# YTM32B1HA0 register map
Vendor: YTMicro; File version: 1.0
CPU: little endian, MPU, FPU, 2 interrupt priority bits
Registers are 32-bit, read-write, reset 0x0 unless marked. A register's access mark holds for its fields unless they carry their own. Offsets are from the block's base; [hi:lo] are bit positions; {n}, {i} and the like mark numbered series; 'fields as' and 'values as' point back to an identical list; <NAME> marks a mode.

## ENET (part 8 of 10) — Ethernet Quality-of-Service
Base 0x401E4000; register names take the prefix ENET_
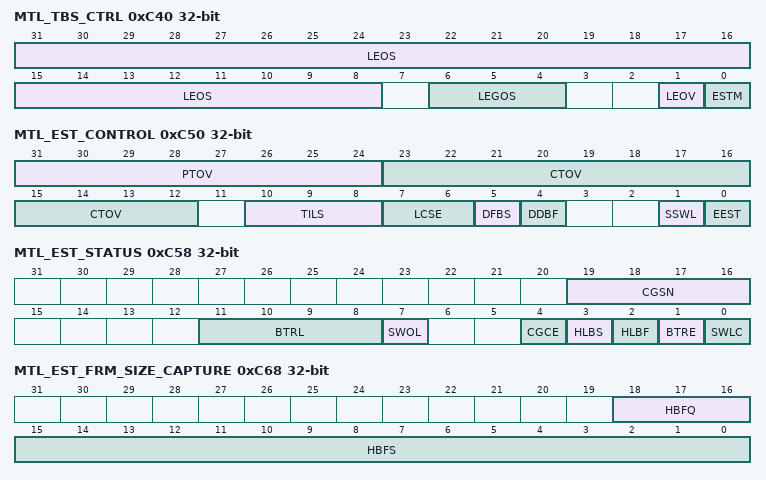
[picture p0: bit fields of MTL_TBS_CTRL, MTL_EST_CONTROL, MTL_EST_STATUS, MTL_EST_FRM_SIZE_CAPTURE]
0xC40 MTL_TBS_CTRL — This register controls the operation of Time Based Scheduling.
  [31:8] LEOS — The value in units of 256 nanoseconds that has to be added to the Launch time to compute the Launch Expiry time. Value valid only when LEOV is set. Max value: 999,999,999 ns, additionally should be smaller than CTR-1 value when ESTM mode is set since this value is a modulo CTR value.
  [6:4] LEGOS — The number GSN slots that has to be added to the Launch GSN to compute the Launch Expiry time. Value valid only when LEOV is set.
  [1] LEOV — When set indicates the LEOS field is valid. When not set, indicates the Launch Expiry Offset is not valid and the MTL must not check for Launch expiry time.
    0=LEOS field is invalid; 1=LEOS field is valid
  [0] ESTM — When this bit is set, the Launch Time value used in Time Based Scheduling is interpreted as an EST offset value and is added to the Base Time Register (BTR) of the current list. When reset, the Launch Time value is used as an absolute value that should be compared with the System time [39:8].
    0=EST offset Mode is disabled; 1=EST offset Mode is enabled
0xC50 MTL_EST_CONTROL — This register controls the operation of Enhancements to Scheduled Transmission (IEEE802.1Qbv).
  [31:24] PTOV — The value of PTP Clock period multiplied by 6 in nanoseconds. This value is needed to avoid transmission overruns at the beginning of the installation of a new GCL.
  [23:12] CTOV — Provides a 12 bit time offset value in nano second that is added to the current time to compensate for all the implementation pipeline delays such as the CDC sync delay, buffering delays, data path delays etc. This offset helps to ensure that the impact of gate controls is visible on the line exactly at the pre-determined schedule (or as close to the schedule as possible).
  [10:8] TILS — This field provides the left shift amount for the programmed Time Interval values used in the Gate Control Lists. ■ 000: No left shift needed (equal to x1ns) ■ 001: Left shift TI by 1 bit (equal to x2ns) ■ 010: Left shift TI by 2 bits (equal to x4ns) ■. ■. ■ 100: Left shift TI by 7 bits (equal to x128ns) Based on the configuration one or more bits of this field should be treated as Reserved/Read-Only.
  [7:6] LCSE — Programmable number of GCL list iterations before reporting an HLBS error defined in EST_Status register.
    0=4 iterations; 1=8 iterations; 2=16 iterations; 3=32 iterations
  [5] DFBS — When set frames reported to cause HOL Blocking due to not getting scheduled (HLBS field of EST_Status register) after 4,8,16,32 (based on LCSE field of this register) GCL iterations are dropped.
    0=Do not Drop Frames causing Scheduling Error; 1=Drop Frames causing Scheduling Error
  [4] DDBF — When set, frames are not be dropped during Head-of-Line blocking due to Frame Size Error (HLBF field of EST_Status register).
    0=Drop frames during Frame Size Error; 1=Do not Drop frames during Frame Size Error
  [1] SSWL — When set indicates that the software has programmed that list that it currently owns (SWOL) and the hardware should switch to the new list based on the new BTR. Hardware clears this bit when the switch to the SWOL happens to indicate the completion of the switch or when an BTR error (BTRE in Status register) is set. When BTRE is set this bit is cleared but SWOL is not updated as the switch was not successful. Access restriction applies. Setting 1 sets. Self-cleared. Setting 0 has no effect.
    0=Switch to S/W owned list is disabled; 1=Switch to S/W owned list is enabled
  [0] EEST — When reset, the gate control list processing is halted and all gates are assumed to be in Open state. Should be set for the hardware to start processing the gate control lists. During the toggle from 0 to 1, the gate control list processing starts only after the SSWL bit it set. When DWC_EQOS_ASP_ECC is selected during the configuration, if any uncorrectable error is detected in the EST memory the hardware will reset this bit and disable the EST function.
    0=EST is disabled; 1=EST is enabled
0xC58 MTL_EST_STATUS ro — This register provides Status related to Enhancements to Scheduled Transmission (IEEE802.1Qbv).
  [19:16] CGSN rw — Indicates the slot number of the GCL list. Slot number is a modulo 16 count of the GCL List loops executed so far. Even if a new GCL list is installed, the count is incremental.
  [11:8] BTRL rw — Provides the minimum count (N) for which the equation Current Time =< New BTR + (N * New Cycle Time) becomes true. N = "1111" indicates the iterations exceeded the value of 8 and the hardware was not able to update New BTR to be equal to or greater than Current Time. Software intervention is needed to update the New BTR. Value cleared when BTRE field of this register is cleared.
  [7] SWOL rw — When '0' indicates Gate control list number "0" is owned by software and when "1" indicates the Gate Control list "1" is owned by the software. Any reads/writes by the software (using indirect access via GCL_Control) is directed to the list indicated by this value by default. The inverse of this value is treated as HWOL. R/W operations performed by hardware are directed to the list pointed by HWOL by default.
    0=Gate control list number "0" is owned by software; 1=Gate control list number "1" is owned by software
  [4] CGCE rw — This error occurs when the list length (LLR) is 1 and the programmed Time Interval (TI) value after the optional Left Shifting is less than or equal to the Cycle Time (CTR). The above programming implies Gates are either always Closed or always Open based on the Gate Control values; the same effect can be achieved by other simpler (non TSN) programming mechanisms. Since the implementation does not support such a programming an error is reported. Access restriction applies. Self-set to 1 on internal event. Setting 1 clears. Setting 0 has no effect.
    0=Constant Gate Control Error not detected; 1=Constant Gate Control Error detected
  [3] HLBS rw — Set when the frame is not able to win arbitration and get scheduled even after 4 iterations of the GCL. Indicates to software a potential programming error. The one hot encoded values of the Queue Numbers that are not able to make progress are indicated in the MTL_EST_Sch_Error register. Bit cleared when MTL_EST_Sch_Error register is all zeros.
    0=Head-Of-Line Blocking due to Sched- uling not detected; 1=Head-Of-Line Blocking due to Scheduling detected
  [2] HLBF rw — Set when HOL Blocking is noticed on one or more Queues as a result of none of the Time Intervals of gate open in the GCL being greater than or equal to the duration needed for frame size (or frame fragment size when preemption is enabled) transmission. The one hot encoded Queue numbers that are experiencing HLBF are indicated in the MTL_EST_Frm_Size_Error register. Additionally, the first Queue number that experienced HLBF along with the frame size is captured in MTL_EST_Frm_Size_Capture register. Bit cleared when MTL_EST_Frame_Size_ Error register is all zeros.
    0=Head-Of-Line Blocking due to Frame Size not detected; 1=Head-Of-Line Blocking due to Frame Size detected
  [1] BTRE rw — When "1" indicates a programming error in the BTR of SWOL where the programmed value is less than current time. If the BTRL = "1111", SWOL is not updated and Software should reprogram the BTR to a value greater than current time and then set SSWL to reinitiate the switch to SWOL. Else if the value of BTRL < "1111", SWOL is updated and this field indicates the number of iterations (of + CycleTime) taken by hardware to update the BTR to a value greater than Current Time. Access restriction applies. Self-set to 1 on internal event. Setting 1 clears. Setting 0 has no effect.
    0=BTR Error not detected; 1=BTR Error detected
  [0] SWLC rw — When "1" indicates the hardware has successfully switched to the SWOL, and the SWOL bit has been updated to that effect. Cleared when the SSWL of EST_Control register transitions from 0 to 1, or on a software write. Access restriction applies. Self-set to 1 on internal event. Setting 1 clears. Setting 0 has no effect.
    0=Switch to S/W owned list is not complete; 1=Switch to S/W owned list is complete
0xC60 MTL_EST_SCH_ERROR ro — This register provides the One Hot encoded Queue Numbers that are having the Scheduling related error (timeout).
  [2:0] SEQN rw — The One Hot Encoded Queue Numbers that have experienced error/timeout described in HLBS field of status register. Access restriction applies. Self-set to 1 on internal event. Setting 1 clears. Setting 0 has no effect.
0xC64 MTL_EST_FRM_SIZE_ERROR — This register provides the One Hot encoded Queue Numbers that are having the Frame Size related error.
  [2:0] FEQN — The One Hot Encoded Queue Numbers that have experienced error described in HLBF field of status register. Access restriction applies. Self-set to 1 on internal event. Setting 1 clears. Setting 0 has no effect.
0xC68 MTL_EST_FRM_SIZE_CAPTURE — This register captures the Frame Size and Queue Number of the first occurrence of the Frame Size related error. Up on clearing it captures the data of immediate next occurrence of a similar error.
  [18:16] HBFQ — Captures the binary value of the of the first Queue (number) experiencing HLBF error (see HLBF field of status register). Value once written is not altered by any subsequent queue errors of similar nature. Once cleared the queue number of the next occurring HLBF error is captured. Width is based on the number of Tx Queues configured; remaining bits are Read-Only. Cleared when MTL_EST_Frm_Size_Error register is all zeros.
  [15:0] HBFS — Captures the Frame Size of the dropped frame related to queue number indicated in HBFQ field of this register. Contents of this register should be considered invalid, if this field is zero. Cleared when MTL_EST_Frm_Size_Error register is all zeros.
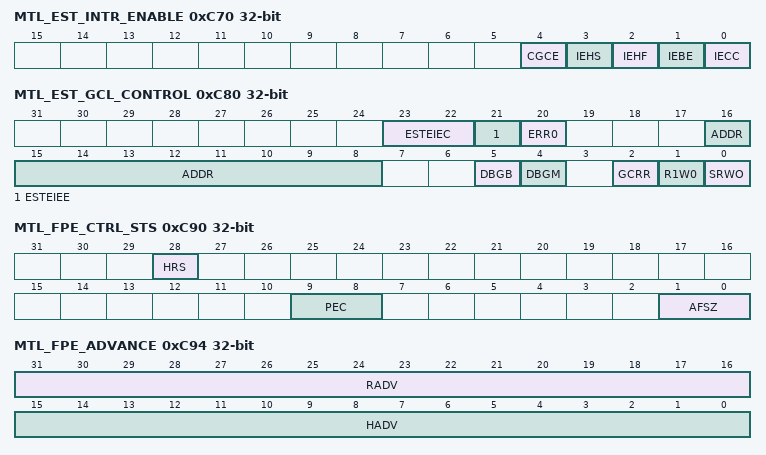
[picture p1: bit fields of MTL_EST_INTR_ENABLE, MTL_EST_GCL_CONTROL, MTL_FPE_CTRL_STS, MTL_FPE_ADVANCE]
0xC70 MTL_EST_INTR_ENABLE — This register implements the Interrupt Enable bits for the various events that generate an interrupt. Bit positions have a 1 to 1 correlation with the status bit positions in MTL_ETS_Status register.
  [4] CGCE — When set, generates interrupt when the Constant Gate Control Error occurs and is indicated in the status. When reset this event does not generate an interrupt
    0=Interrupt for CGCE is disabled; 1=Interrupt for CGCE is enabled
  [3] IEHS — When set, generates interrupt when the Head-of-Line Blocking due to Scheduling issue and is indicated in the status. When reset this event does not generate an interrupt.
    0=Interrupt for HLBS is disabled; 1=Interrupt for HLBS is enabled
  [2] IEHF — When set, generates interrupt when the Head-of-Line Blocking due to Frame Size error occurs and is indicated in the status. When reset this event does not generate an interrupt.
    0=Interrupt for HLBF is disabled; 1=Interrupt for HLBF is enabled
  [1] IEBE — When set, generates interrupt when the BTR Error occurs and is indicated in the status. When reset this event does not generate an interrupt.
    0=Interrupt for BTR Error is disabled; 1=Interrupt for BTR Error is enabled
  [0] IECC — When set, generates interrupt when the configuration change is successful and the hardware has switched to the new list. When reset this event does not generate an interrupt.
    0=Interrupt for Switch List is disabled; 1=Interrupt for Switch List is enabled
0xC80 MTL_EST_GCL_CONTROL — This register provides the control information for reading/writing to the Gate Control lists.
  [23:22] ESTEIEC — When EIEE bit of this register is set, following are the errors inserted based on the value encoded in this field. This filed will be valid only if DWC_EQOS_ASP_ECC feature is selected during the configuration, else it will be reserved.
    0=Insert 1 bit error; 1=Insert 2 bit errors; 2=Insert 3 bit errors; 3=Insert 1 bit error in address field
  [21] ESTEIEE — When set along with EEST bit of MTL_EST_Control register, enables the ECC error injection feature. When reset, disables the ECC error injection feature.
    0=EST ECC Inject Error is disabled; 1=EST ECC Inject Error is enabled
  [20] ERR0 — When set indicates the last write operation was aborted as software writes to GCL and GCL registers is prohibited when SSWL bit of MTL_EST_Control Register is set. Access restriction applies. Self-set to 1 on internal event. Setting 1 clears. Setting 0 has no effect.
    0=ERR0 is disabled; 1=ERR1 is enabled
  [16:8] ADDR — Gate Control List Address: (GCLA when GCRR is "0"). Provides the address (row number) of the Gate Control List at which the R/W operation has to be performed. By default the Gate Control List pointed by SWOL of MTL_EST_Status is selected for R/W, however if the DBGM bit of this register is set, a debug mode access is given to R/W from DBGB. The width of this field is dependent on DWC_EQOS_EST_DEP; unused bits should be treated as read only. Gate Control list Related Registers Address: (GCRA when GCRR is "1"). By default the GCL related register set pointed by SWOL of MTL_EST_Status is selected for R/W, however if the DBGM bit of this register is set, a debug mode access is given to R/W from DBGB. Lower 3 bits are only used in this mode, higher order bits are treated as dont cares. ■ 000: BTR Low (31:0) ■ 001: BTR High (63:31) ■ 010: CTR Low (31:0) ■ 011: CTR High (39:32) ■ 100: TER (31:0) ■ 101: LLR (n:0) (where n is (log{DWC_EQOS_EST_DEP} / log2)) ■ Others: Reserved
  [5] DBGB — When set to "0" indicates R/W in debug mode should be directed to Bank 0 (GCL0 and corresponding Time related registers). When set to "1" indicates R/W in debug mode should be directed to Bank 1 (GCL1 and corresponding Time related registers). This value is used when DBGM is set and overrides by value of SWOL which is normally used.
  [4] DBGM — When set to "1" indicates R/W in debug mode where the memory bank (for GCL and Time related registers) is explicitly provided by DBGB value, when set to "0" SWOL bit is used to determine which bank to use.
    0=Debug Mode is disabled; 1=Debug Mode is enabled
  [2] GCRR — When set to "1" indicates the R/W access is for the GCL related registers (BTR, CTR, TER, LLR) whose address is provided by GCRA. When "0" indicates R/W should be directed to GCL from the address provided by GCLA.
    0=Gate Control Related Registers are disabled; 1=Gate Control Related Registers are enabled
  [1] R1W0 — When set to '1': Read Operation When set to '0': Write Operation.
    0=Write Operation; 1=Read Operation
  [0] SRWO — When set indicates a Read/Write Op has started and is in progress. When reset by hardware indicates the R/W Op has completed or an error has occurred (when bit 20 is set) Reads: Data can be read from MTL_EST_GCL_Data register after this bit is reset Writes: MTL_EST_GCL_Data should be programmed with write data before setting SRWO. Access restriction applies. Setting 1 sets. Self-cleared. Setting 0 has no effect.
    0=Start Read/Write Op disabled; 1=Start Read/Write Op enabled
0xC84 MTL_EST_GCL_DATA — This register holds the read data or write data in case of reads and writes respectively.
  [31:0] GCD — The data corresponding to the address selected in the GCL_Control register. Used for both Read and Write operations.
0xC90 MTL_FPE_CTRL_STS — This register controls the operation of, and provides status for Frame Preemption (IEEE802.1Qbu/802.3br).
  [28] HRS ro — ■ 1: Indicates a Set-and-Hold-MAC operation was last executed and the pMAC is in Hold State. ■ 0: Indicates a Set-and-Release-MAC operation was last executed and the pMAC is in Release State.
    0=Indicates a Set-and-Release-MAC operation was last executed and the pMAC is in Release State; 1=Indicates a Set-and-Hold-MAC operation was last executed and the pMAC is in Hold State
  [9:8] PEC — When set indicates the corresponding Queue must be classified as preemptable, when '0' Queue is classified as express. When both EST (Qbv) and Preemption are enabled, Queue-0 is always assumed to be preemptable. When EST (Qbv) is enabled Queues categorized as preemptable here are always assumed to be in "Open" state in the Gate Control List.
  [1:0] AFSZ — used to indicate, in units of 64 bytes, the minimum number of bytes over 64 bytes required in non-final fragments of preempted frames. The minimum non-final fragment size is (AFSZ +1) * 64 bytes
0xC94 MTL_FPE_ADVANCE — This register holds the Hold and Release Advance time.
  [31:16] RADV — The maximum time in nanoseconds that can elapse between issuing a RELEASE to the MAC and the MAC being ready to resume transmission of preemptable frames, in the absence of there being any express frames available for transmission.
  [15:0] HADV — The maximum time in nanoseconds that can elapse between issuing a HOLD to the MAC and the MAC ceasing to transmit any preemptable frame that is in the process of transmission or any preemptable frames that are queued for transmission.
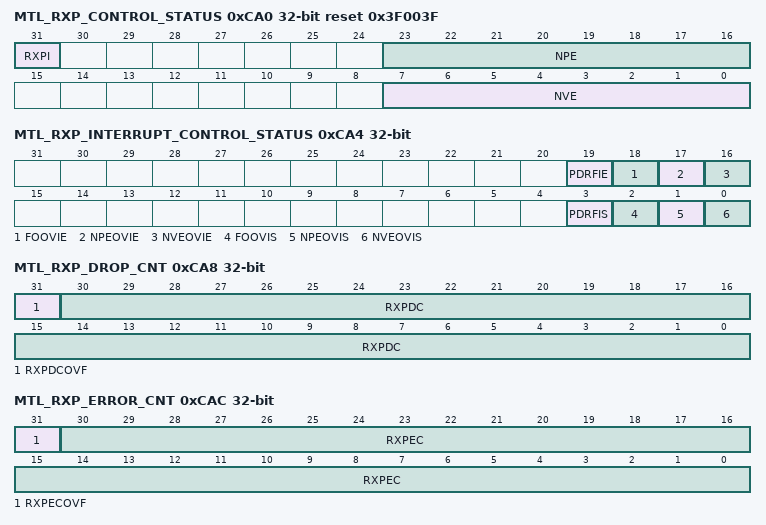
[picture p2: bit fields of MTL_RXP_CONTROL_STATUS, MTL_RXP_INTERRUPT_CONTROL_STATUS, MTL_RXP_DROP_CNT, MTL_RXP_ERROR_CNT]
0xCA0 MTL_RXP_CONTROL_STATUS reset 0x3F003F — The MTL_RXP_Control_Status register establishes the operating mode of Rx Parser and provides some status.
  [31] RXPI ro — This status bit is set to 1 when the Rx parser is in Idle State and waiting for a new packet for processing. This bit is used as a handshake with software when parser gets disables. After disabling, when bit is set then software can update the Rx parser instruction table.
    0=RX Parser not in Idle state; 1=RX Parser in Idle state
  [23:16] NPE — This control indicates the number of parsable entries in the Instruction Memory. This is used in Rx parser logic to detect programming Error. In case number of parsed entries for a packet is more than this entry then NPEOVIS bit in the MTL_RXP_Interrupt_Control_Status register is set.
  [7:0] NVE — This control indicates the number of valid entries in the Instruction Memory. This is used in Rx parser logic to detect any programming Error. In case while parsing Table address (memory address) found to be more than this entry then NVEOVIS bit in the MTL_RXP_Interrupt_Control_Status register is set. Note: The minimum value of this should be 2.
0xCA4 MTL_RXP_INTERRUPT_CONTROL_STATUS — The MTL_RXP_Interrupt_Control_Status registers provides enable control for the inter- rupts and provides interrupt status.
  [19] PDRFIE — When this bit is set, the PDRFIS interrupt is enabled. When this bit is reset, the PDRFIS interrupt is disabled.
    0=Packet Drop due to RF Interrupt is disabled; 1=Packet Drop due to RF Interrupt is enabled
  [18] FOOVIE — When this bit is set, the FOOVIS interrupt is enabled. When this bit is reset, the FOOVIS interrupt is disabled.
    0=Frame Offset Overflow Interrupt is disabled; 1=Frame Offset Overflow Interrupt is enabled
  [17] NPEOVIE — When this bit is set, the NPEOVIS interrupt is enabled. When this bit is reset, the NPEOVIS interrupt is disabled.
    0=Number of Parsable Entries Overflow Interrupt is disabled; 1=Number of Parsable Entries Overflow Interrupt is enabled
  [16] NVEOVIE — When this bit is set, the NVEOVIS interrupt is enabled. When this bit is reset, the NVEOVIS interrupt is disabled.
    0=Number of Valid Entries Overflow Interrupt is disabled; 1=Number of Valid Entries Overflow Interrupt is enabled
  [3] PDRFIS — If the Rx Parser result says to drop the packet by setting RF=1 in the instruction memory, then this bit is set to 1. This bit is cleared when the application writes 1 to this bit. Access restriction applies. Self-set to 1 on internal event. Setting 1 clears. Setting 0 has no effect.
    0=Packet Dropped due to RF Interrupt Status not detected; 1=Packet Dropped due to RF Interrupt Status detected
  [2] FOOVIS — While parsing if the Instruction table entry's 'Frame Offset' found to be more than EOF offset, then then this bit is set. This bit is cleared when the application writes 1 to this bit. Access restriction applies. Self-set to 1 on internal event. Setting 1 clears. Setting 0 has no effect.
    0=Frame Offset Overflow Interrupt Status not detected; 1=Frame Offset Overflow Interrupt Status detected
  [1] NPEOVIS — While parsing a packet if the number of parsed entries found to be more than NPE[] (Number of Parseable Entries in MTL_RXP_Control register),then this bit is set to 1. This bit is cleared when the application writes 1 to this bit. Access restriction applies. Self-set to 1 on internal event. Setting 1 clears. Setting 0 has no effect.
    0=Number of Parsable Entries Overflow Interrupt Status not detected; 1=Number of Parsable Entries Overflow Interrupt Status detected
  [0] NVEOVIS — While parsing if the Instruction address found to be more than NVE (Number of Valid Entries in MTL_RXP_Control register), then this bit is set to 1. This bit is cleared when the application writes 1 to this bit. Access restriction applies. Self-set to 1 on internal event. Setting 1 clears. Setting 0 has no effect.
    0=Number of Valid Entries Overflow Interrupt Status not detected; 1=Number of Valid Entries Overflow Interrupt Status detected
0xCA8 MTL_RXP_DROP_CNT ro — TThe MTL_RXP_Drop_Cnt register provides the drop count of Rx Parser initiated drops.
  [31] RXPDCOVF rw — When set, this bit indicates that the MTL_RXP_Drop_cnt (RXPDC) Counter field crossed the maximum limit. Access restriction applies. Clears on read. Self-set to 1 on internal event.
    0=Rx Parser Drop count overflow not occurred; 1=Rx Parser Drop count overflow occurred
  [30:0] RXPDC rw — This 31-bit counter is implemented whenever a Rx Parser Drops a packet due to RF =1. The counter is cleared when the register is read.
0xCAC MTL_RXP_ERROR_CNT ro — The MTL_RXP_Error_Cnt register provides the Rx Parser related error occurrence count.
  [31] RXPECOVF rw — When set, this bit indicates that the MTL_RXP_Error_cnt (RXPEC) Counter field crossed the maximum limit. Access restriction applies. Clears on read. Self-set to 1 on internal event.
    0=Rx Parser Error count overflow not occurred; 1=Rx Parser Error count overflow occurred
  [30:0] RXPEC rw — This 31-bit counter is implemented whenever a Rx Parser encounters following Error scenarios ■ Entry address >= NVE[] ■ Number Parsed Entries >= NPE[] ■ Entry address > EOF data entry address The counter is cleared when the register is read.
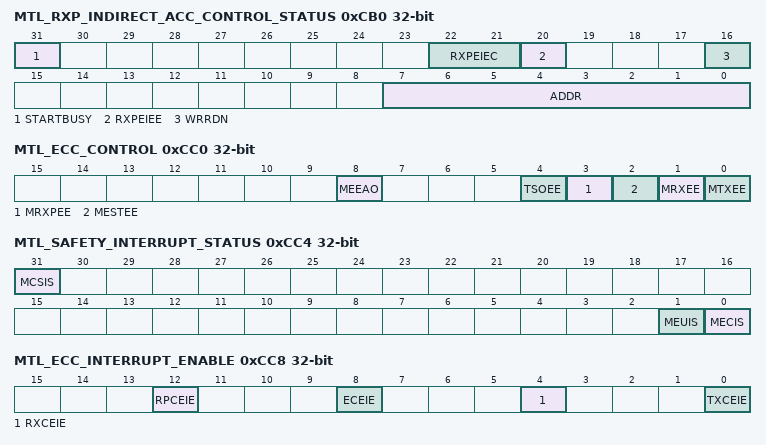
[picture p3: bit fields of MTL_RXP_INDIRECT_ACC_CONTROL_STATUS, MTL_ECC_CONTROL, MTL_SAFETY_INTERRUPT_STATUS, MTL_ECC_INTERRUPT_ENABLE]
0xCB0 MTL_RXP_INDIRECT_ACC_CONTROL_STATUS — The MTL_RXP_Indirect_Acc_Control_Status register provides the Indirect Access control and status for Rx Parser memory.
  [31] STARTBUSY — When this bit is set to 1 by the software then it indicates to start the Read/Write operation from/to the Rx Parser Memory. Software should read this bit as 0 before issuing read or write request to access the Parser Memory Instructions. This bit when set to 1 indicates that hardware is busy until its gets cleared by hardware and software should not issue any read or write operation.
    0=hardware not busy; 1=hardware is busy (Read/Write operation from/to the Rx Parser Memory)
  [22:21] RXPEIEC — When EIEE bit of this register is set, following are the errors inserted based on the value encoded in this field.
    values as MTL_EST_GCL_CONTROL.ESTEIEC
  [20] RXPEIEE — When set, enables the ECC error injection feature. When reset, disables the ECC error injection feature.
    0=ECC Inject Error for Rx Parser Memory is disabled; 1=ECC Inject Error for Rx Parser Memory is enabled
  [16] WRRDN — When this bit is set to 1 indicates the write operation to the Rx Parser Memory. When this bit is set to 0 indicates the read operation to the Rx Parser Memory.
    0=Read operation to the Rx Parser Memory; 1=Write operation to the Rx Parser Memory
  [7:0] ADDR — This field indicates the ADDR of the 32-bit entry in Rx parser instruction table. Each entry has 128-bit (4x32-bit words). The X depends on the configurable DWC_EQOS_FRP_ENTRIES If DWC_EQOS_FRP_ENTRIES == 256 , then X = 9 If DWC_EQOS_FRP_ENTRIES = 128 , then X = 8 IF DWC_EQOS_FRP_ENTRIES = 64, then X = 7 This is can be written by the software before issuing any Read/Write command. The hardware auto-increments this field after the read-write operation gets completed.
0xCB4 MTL_RXP_INDIRECT_ACC_DATA ro — The MTL_RXP_Indirect_Acc_Data registers holds the data associated to Indirect Access to Rx Parser memory.
  [31:0] DATA rw — Software should write this register before issuing any write command. The hardware provides the read data from the Rx Parser Memory for read operation when STARTBUSY =0 after read command.
0xCC0 MTL_ECC_CONTROL — The MTL_ECC_Control register establishes the operating mode of ECC related to MTL memories.
  [8] MEEAO — When set, the following error address fields will hold the last valid address where the error is detected. When reset, the following error address fields will hold the first address where the error is detected. EUEAS/ECEAS of MTL_ECC_Err_Addr_Status register.
    0=MTL ECC Error Address Status Over-ride is disabled; 1=MTL ECC Error Address Status Over-ride is enabled
  [4] TSOEE — When set to 1, enables the ECC feature for TSO memory in DMA. When set to zero, disables the ECC feature for TSO memory in DMA.
    0=TSO memory ECC is disabled; 1=TSO memory ECC is enabled
  [3] MRXPEE — When set to 1, enables the ECC feature for Rx Parser memory. When set to zero, disables the ECC feature for Rx Parser memory.
    0=MTL Rx Parser ECC is disabled; 1=MTL Rx Parser ECC is enabled
  [2] MESTEE — When set to 1, enables the ECC feature for EST memory. When set to zero, disables the ECC feature for EST memory.
    0=MTL EST ECC is disabled; 1=MTL EST ECC is enabled
  [1] MRXEE — When set to 1, enables the ECC feature for MTL Rx FIFO memory. When set to zero, disables the ECC feature for MTL Rx FIFO memory.
    0=MTL Rx FIFO ECC is disabled; 1=MTL Rx FIFO ECC is enabled
  [0] MTXEE — When set to 1, enables the ECC feature for MTL Tx FIFO memory. When set to zero, disables the ECC feature for MTL Tx FIFO memory.
    0=MTL Tx FIFO ECC is disabled; 1=MTL Tx FIFO ECC is enabled
0xCC4 MTL_SAFETY_INTERRUPT_STATUS ro — The MTL_Safety_Interrupt_Status registers provides Safety interrupt status.
  [31] MCSIS rw — Indicates an uncorrectable Safety-related Interrupt is set in the MAC module. MAC_DPP_FSM_Interrupt_Status register should be read when this bit is set, to get the cause of the Safety Interrupt in MAC.
    0=MAC Safety Uncorrectable Interrupt Status not detected; 1=MAC Safety Uncorrectable Interrupt Status detected
  [1] MEUIS rw — This bit indicates that an uncorrectable error interrupt event in the MTL ECC safety feature. To get the exact cause of the interrupt the application should read the MTL_ECC_Interrupt_Status register.
    0=MTL ECC Uncorrectable error Interrupt Status not detected; 1=MTL ECC Uncorrectable error Interrupt Status detected
  [0] MECIS rw — This bit indicates that a correctable error interrupt event in the MTL ECC safety feature. To get the exact cause of the interrupt the application should read the MTL_ECC_Interrupt_Status register.
    0=MTL ECC Correctable error Interrupt Status not detected; 1=MTL ECC Correctable error Interrupt Status detected
0xCC8 MTL_ECC_INTERRUPT_ENABLE — The MTL_ECC_Interrupt_Enable register provides enable bits for the ECC interrupts.
  [12] RPCEIE — When set, generates an interrupt when an uncorrectable error is detected at the Rx Parser memory interface. It is indicated in RPCES status bit of MTL_ECC_Interrupt_Status register. When reset this event does not generates an interrupt.
    0=Rx Parser memory Correctable Error Interrupt is disabled; 1=Rx Parser memory Correctable Error Inter- rupt is enabled
  [8] ECEIE — When set, generates an interrupt when a correctable error is detected at the MTL EST memory interface. It is indicated in the ECES bit of MTL_ECC_Interrupt_Status register. When reset this event does not generates an interrupt.
    0=EST memory Correctable Error Interrupt is disabled; 1=EST memory Correctable Error Interrupt is enabled
  [4] RXCEIE — When set, generates an interrupt when a correctable error is detected at the MTL Rx memory interface. It is indicated in the RXCES bit of MTL_ECC_Interrupt_Status register. When reset this event does not generates an interrupt.
    0=Rx memory Correctable Error Interrupt is disabled; 1=Rx memory Correctable Error Interrupt is enabled
  [0] TXCEIE — When set, generates an interrupt when a correctable error is detected at the MTL Tx memory interface. It is indicated in the TXCES bit of MTL_ECC_Interrupt_Status register. When reset this event does not generates an interrupt.
    0=Tx memory Correctable Error Interrupt is disabled; 1=Tx memory Correctable Error Interrupt is enabled
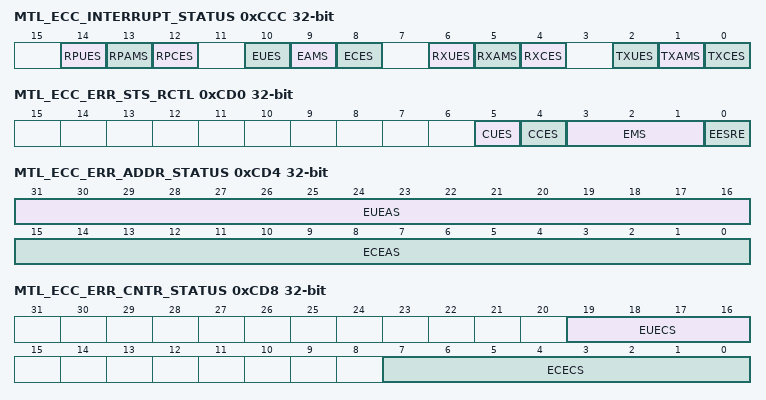
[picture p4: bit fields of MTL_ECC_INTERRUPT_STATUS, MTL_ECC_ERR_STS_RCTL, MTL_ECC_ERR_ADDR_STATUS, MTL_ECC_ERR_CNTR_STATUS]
0xCCC MTL_ECC_INTERRUPT_STATUS — The MTL_ECC_Interrupt_Status register provides MTL ECC Interrupt Status.
  [14] RPUES — When set, indicates that an uncorrectable error is detected at Rx Parser memory interface.
    0=Rx Parser memory Uncorrectable Error Status not detected; 1=Rx Parser memory Uncorrectable Error Status detected
  [13] RPAMS — This bit when set indicates that address mismatch is found for address bus of Rx Parser memory.
    0=MTL Rx Parser memory Address Mismatch Status not detected; 1=MTL Rx Parser memory Address Mismatch Status detected
  [12] RPCES — This bit when set indicates that correctable error is detected at RX Parser memory interface.
    0=MTL Rx Parser memory Correctable Error Status not detected; 1=MTL Rx Parser memory Correctable Error Status detected
  [10] EUES — When set, indicates that an uncorrectable error is detected at MTL EST memory interface.
    0=MTL EST memory Uncorrectable Error Status not detected; 1=MTL EST memory Uncorrectable Error Status detected
  [9] EAMS — This bit when set indicates that address mismatch is found for address bus of MTL EST memory.
    0=MTL EST memory Address Mismatch Status not detected; 1=MTL EST memory Address Mismatch Status detected
  [8] ECES — This bit when set indicates that correctable error is detected at the MTL EST memory.
    0=MTL EST memory Correctable Error Status not detected; 1=MTL EST memory Correctable Error Status detected
  [6] RXUES — When set, indicates that an uncorrectable error is detected at MTL Rx memory interface.
    0=MTL Rx memory Uncorrectable Error Status not detected; 1=MTL Rx memory Uncorrectable Error Status detected
  [5] RXAMS — This bit when set indicates that address mismatch is found for address bus of MTL Rx memory.
    0=MTL Rx memory Address Mismatch Status not detected; 1=MTL Rx memory Address Mismatch Status detected
  [4] RXCES — This bit when set indicates that correctable error is detected at the MTL Rx memory.
    0=MTL Rx memory Correctable Error Status not detected; 1=MTL Rx memory Correctable Error Status detected
  [2] TXUES — When set, indicates that an uncorrectable error is detected at MTL Tx memory interface.
    0=MTL Tx memory Uncorrectable Error Status not detected; 1=MTL Tx memory Uncorrectable Error Status detected
  [1] TXAMS — This bit when set indicates that address mismatch is found for address bus of MTL Tx memory.
    0=MTL Tx memory Address Mismatch Status not detected; 1=MTL Tx memory Address Mismatch Status detected
  [0] TXCES — This bit when set indicates that correctable error is detected at the MTL Tx memory.
    0=MTL Tx memory Correctable Error Status not detected; 1=MTL Tx memory Correctable Error Status detected
0xCD0 MTL_ECC_ERR_STS_RCTL — The MTL_ECC_Err_Sts_Rctl register establishes the control for ECC Error status capture.
  [5] CUES — When this bit is set along with EESRE bit of this register, based on the EMS field of this register, the respective memory's uncorrectable error address and uncorrectable error count values will be cleared upon reading. Hardware resets this bit when all the error status values are cleared.
    0=Clear Uncorrectable Error Status not detected; 1=Clear Uncorrectable Error Status detected
  [4] CCES — When this bit is set along with EESRE bit of this register, based on the EMS field of this register, the respective memory's correctable error address and correctable error count values will be cleared upon reading. Hardware resets this bit when all the error status values are cleared.
    0=Clear Correctable Error Status not detected; 1=Clear Correctable Error Status detected
  [3:1] EMS — When EESRE bit of this register is set, this field indicates which memory's error status value to be read. The memory selection encoding is as described below.
    0=MTL Tx memory; 1=MTL Rx memory; 2=MTL EST memory; 3=MTL Rx Parser memory; 4=DMA TSO memory
  [0] EESRE — When this bit is set, based on the EMS field of this register, the respective memory's error status values will be captured as described below ■ The correctable and uncorrectable error count values will be captured into MTL_ECC_Err_Cnt_Status register ■ The address location's of correctable and uncorrectable errors will be captured into MTL_ECC_Err_Addr_Status register. Hardware resets this bit when all the status values are captured into the MTL_ECC_Err_Cnt_Status and MTL_ECC_Err_Addr_Status registers.
    0=MTL ECC Error Status Read is disabled; 1=MTL ECC Error Status Read is enabled
0xCD4 MTL_ECC_ERR_ADDR_STATUS ro — The MTL_ECC_Err_Addr_Status register provides the memory addresses for the correctable and uncorrectable errors.
  [31:16] EUEAS rw — Based on the EMS field of MTL_ECC_Err_Sts_Rctl register, this field holds the respective memory's address locations for which an uncorrectable error or address mismatch is detected. When MEEAO bit of MTL_ECC_Control register is set, this field holds the last valid address of memory for which either an uncorrectable error or an address mismatch is detected. When MEEAO bit of MTL_ECC_Control register is reset, this field holds the first address of the memory for which either an uncorrectable error or address mismatch is detected.
  [15:0] ECEAS rw — Based on the EMS field of MTL_ECC_Err_Sts_Rctl register, this field holds the respective memory's address locations for which a correctable error is detected. When MEEAO bit of MTL_ECC_Control register is set, this field holds the last valid address of memory for which correctable error or address mismatch is detected. When MEEAO bit of MTL_ECC_Control register is reset, this field holds the first address of the memory for which correctable error is detected.
0xCD8 MTL_ECC_ERR_CNTR_STATUS ro — The MTL_ECC_Err_Cntr_Status register provides ECC Error count for Correctable and uncorrectable errors.
  [19:16] EUECS rw — Based on the EMS field of MTL_ECC_Err_Cntr_Rctl register, this field holds the respective memory's uncorrectable error count value.
  [7:0] ECECS rw — Based on the EMS field of MTL_ECC_Err_Cntr_Rctl register, this field holds the respective memory's correctable error count value.
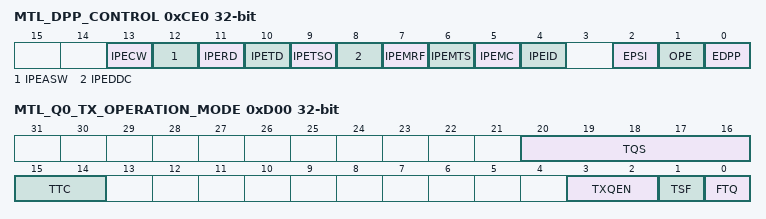
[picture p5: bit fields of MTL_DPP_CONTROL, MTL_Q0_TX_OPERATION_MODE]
0xCE0 MTL_DPP_CONTROL — he MTL_DPP_Control establishes the operating mode of Data Parity protection and error injection.
  [13] IPECW — When set to 1, parity bit of first valid data generated by the CSR parity generator (or at PG10 as shown in Fig.AXI slave Interface Data path parity protection) is flipped. Hardware will clear this bit once respective parity bit is flipped.
    0=Insert Parity error in CSR Read data parity generator is disabled; 1=Insert Parity error in CSR Read data parity generator is enabled
  [12] IPEASW — When set to 1, parity bit of first valid data generated by the AXI parity generator is (or at PG9 as shown in Fig.AXI slave Interface Data path parity protection) flipped. Hardware will clear this bit once respective parity bit is flipped.
    0=Insert Parity error in AXI Slave Write data parity generator is disabled; 1=Insert Parity error in AXI Slave Write data parity generator is enabled
  [11] IPERD — When set to 1, parity bit of first valid data generated by the DMA Rx write-back descriptor parity generator(or at PG8 as shown in Fig.Receive data path parity protection) is flipped.
    0=Insert Parity error in Rx write-back Descriptor parity generator is disabled; 1=Insert Parity error in Rx write-back Descriptor parity generator is enabled
  [10] IPETD — When set to 1, parity bit of first valid data generated by the DMA Tx write-back descriptor parity generator(or at PG4 as shown in Fig.Transmit data path parity protection) is flipped. Hardware will clear this bit once respective parity bit is flipped.
    0=Insert Parity error in Tx write-back Descriptor parity generator is disabled; 1=Insert Parity error in Tx write-back Descriptor parity generator is enabled
  [9] IPETSO — When set to 1, parity bit of first valid data generated by the DMA TSO parity generator is (or at PG3 as shown in Fig.Transmit data path parity protection) flipped. Hardware will clear this bit once respective parity bit is flipped.
    0=Insert Parity Error in DMA TSO parity generator is disabled; 1=Insert Parity Error in DMA TSO parity generator is enabled
  [8] IPEDDC — When set to 1, parity bit of first valid data generated by the DMA DTX Control word parity generator (or at PG2 as shown in Fig.Transmit data path parity protection) is flipped. Hardware will clear this bit once respective parity bit is flipped.
    0=Insert Parity Error in DMA DTX Control word parity generator is disabled; 1=Insert Parity Error in DMA DTX Control word parity generator is enabled
  [7] IPEMRF — When set to 1, parity bit of first valid data generated by the MTL Rx FIFO read control parity generator (or at PG7 as shown in Fig.Receive data path parity protection) is flipped. Hardware will clear this bit once respective parity bit is flipped.
    0=Insert Parity Error in MTL Rx FIFO read control parity generator is disabled; 1=Insert Parity Error in MTL Rx FIFO read control parity generator is enabled
  [6] IPEMTS — When set to 1, parity bit of first valid data generated by the MTL Tx Status parity generator (or at PG6 as shown in Fig.Transmit data path parity protection) is flipped. Hardware will clear this bit once respective parity bit is flipped.
    0=Insert Parity Error in MTL Tx Status parity generator is disabled; 1=Insert Parity Error in MTL Tx Status parity generator is enabled
  [5] IPEMC — When set to 1, parity bit of first valid data generated by the MTL checksum parity generator (or at PG5 as shown in Fig.Transmit data path parity protection) is flipped. Hardware will clear this bit once the respective parity bit is flipped.
    0=Insert Parity Error in MTL checksum parity generator is disabled; 1=Insert Parity Error in MTL checksum parity generator is enabled
  [4] IPEID — When set to 1, parity bit of first valid input data generated by the Interface data parity generator (or at PG1 as shown in Fig.Transmit data path parity protection) is flipped. Following are the input data bus on which parity bits are generated based on configuration selected In AHB Config, hrdata_i In AXI config, rdata_m_i In DMA Config, mdc_rdata_i In MTL Config, ati_data_i Hardware will clear this bit once the respective parity bit is flipped.
    0=Insert Parity Error in Interface Data parity generator is disabled; 1=Insert Parity Error in Interface Data parity generator is enabled
  [2] EPSI — When set to 1, enables the parity check for the slave interface ports and disables the internal generation of parity for the input slave data port. When set to 0, disables the parity check for the slave interface ports and enables the internal parity generation for the input slave data port.
    0=Parity on Slave Interface port is disabled; 1=Parity on Slave Interface port is enabled
  [1] OPE — When set to 1, enables odd parity protection on all the external interfaces and when set to 0, enables even parity protection on all the external interfaces.
    0=Odd Parity is disabled; 1=Odd Parity is enabled
  [0] EDPP — When set to 1, enables the parity protection for EQOS datapath by generating and checking the parity on EQOS datapath. When set to 0, disables the parity protection for EQOS datapath.
    0=Data path Parity Protection is disabled; 1=Data Path Parity Protection is enabled
0xD00 MTL_Q0_TX_OPERATION_MODE — The Queue n Transmit Operation Mode register establishes the Transmit queue operating modes and commands.
  [20:16] TQS — This field indicates the size of the allocated Transmit queues in blocks of 256 bytes. The TQS field is read-write only if the number of Tx Queues more than one, the reset value is 0x0 and indicates size of 256 bytes. When the number of Tx Queues is one, the field is read-only and the configured TX FIFO size in blocks of 256 bytes is reflected in the reset value. The width of this field depends on the Tx memory size selected in your configuration. For example, if the memory size is 2048, the width of this field is 3 bits: LOG2(2048/256) = LOG2(8) = 3 bits
  [15:14] TTC — These bits control the threshold level of the MTL Tx Queue. The transmission starts when the packet size within the MTL Tx Queue is larger than the threshold. In addition, full packets with length less than the threshold are also transmitted. These bits are used only when the TSF bit is reset.
    0=32; 1=64; 2=96; 3=128; 4=192; 5=256; 6=384; 7=512
  [3:2] TXQEN — This field is used to enable/disable the transmit queue 0. ■ 2'b00: Not enabled ■ 2'b01: Reserved ■ 2'b10: Enabled ■ 2'b11: Reserved This field is Read Only in Single Queue configurations and Read Write in Multiple Queue configurations. Note: In multiple Tx queues configuration, all the queues are disabled by default. Enable the Tx queue by programming this field.
    0=Not enabled; 1=Enable in AV mode (Reserved in non-AV); 2=Enabled
  [1] TSF — When this bit is set, the transmission starts when a full packet resides in the MTL Tx queue. When this bit is set, the TTC values specified in Bits[6:4] of this register are ignored. This bit should be changed only when the transmission is stopped.
    0=Transmit Store and Forward is disabled; 1=Transmit Store and Forward is enabled
  [0] FTQ — When this bit is set, the Tx queue controller logic is reset to its default values. Therefore, all the data in the Tx queue is lost or flushed. This bit is internally reset when the flushing operation is complete. Until this bit is reset, you should not write to the MTL_TxQ1_Operation_Mode register. The data which is already accepted by the MAC transmitter is not flushed. It is scheduled for transmission and results in underflow and runt packet transmission. Note: The flush operation is complete only when the Tx queue is empty and the application has accepted the pending Tx Status of all transmitted packets. To complete this flush operation, the PHY Tx clock (clk_tx_i) should be active. Access restriction applies. Setting 1 sets. Self-cleared. Setting 0 has no effect.
    0=Flush Transmit Queue is disabled; 1=Flush Transmit Queue is enabled
